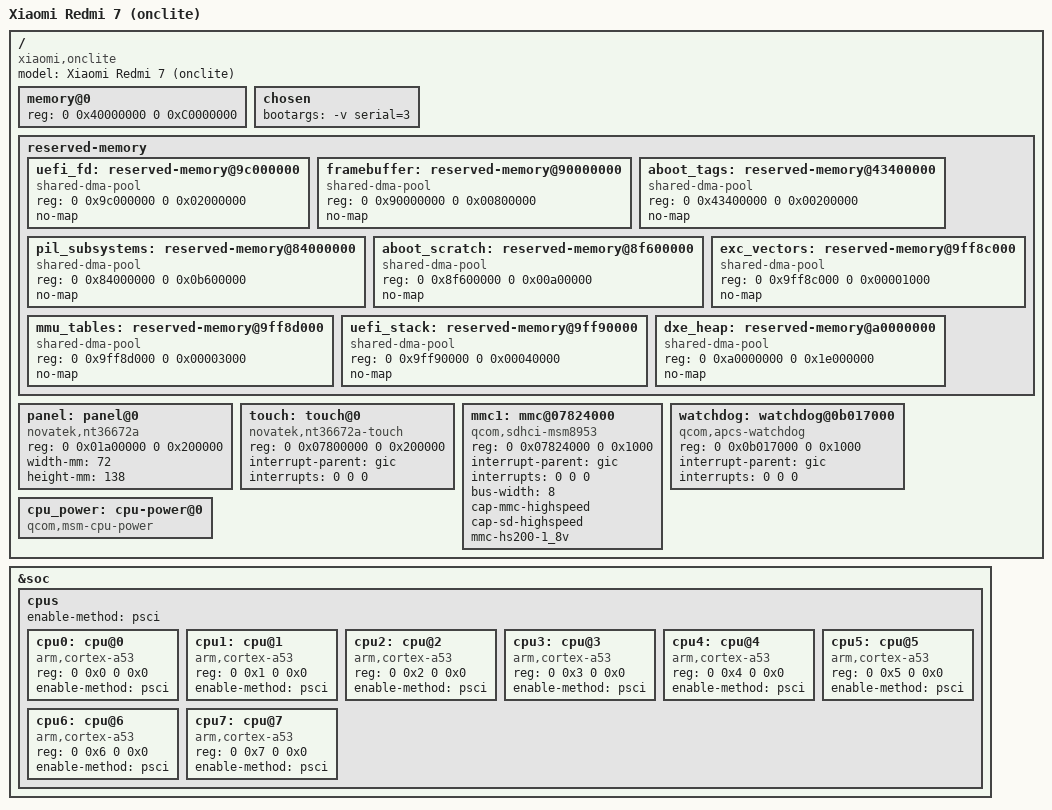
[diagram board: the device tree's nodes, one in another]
/dts-v1/;
/include/ "msm8953.dtsi"

/ {
    model = "Xiaomi Redmi 7 (onclite)";
    compatible = "xiaomi,onclite", "qcom,msm8953";

    // 3 GiB LPDDR3: Bank0 0x40000000-0x80000000 + Bank1 0x80000000-0x100000000
    memory@0 {
        device_type = "memory";
        reg = <0 0x40000000 0 0xC0000000>;
    };

    chosen {
        bootargs = "-v serial=3";
    };

    reserved-memory {
        #address-cells = <2>;
        #size-cells = <2>;
        ranges;

        // UEFI Firmware Device (32 MiB)
        uefi_fd: reserved-memory@9c000000 {
            compatible = "shared-dma-pool", "qcom,uefi-fd";
            reg = <0 0x9c000000 0 0x02000000>;
            no-map;
        };

        // FrameBuffer Continuous Splash (MDP5 scanout, 720x1520 32bpp)
        framebuffer: reserved-memory@90000000 {
            compatible = "shared-dma-pool", "qcom,framebuffer";
            reg = <0 0x90000000 0 0x00800000>;
            no-map;
        };

        // ABOOT tags & Flattened Device Tree
        aboot_tags: reserved-memory@43400000 {
            compatible = "shared-dma-pool", "qcom,aboot-tags";
            reg = <0 0x43400000 0 0x00200000>;
            no-map;
        };

        // PIL Subsystems (Modem, ADSP, WCNSS, Venus, SMEM)
        pil_subsystems: reserved-memory@84000000 {
            compatible = "shared-dma-pool", "qcom,pil-subsystems";
            reg = <0 0x84000000 0 0x0b600000>;
            no-map;
        };

        // ABOOT / lk2nd Execution & Scratch Region
        aboot_scratch: reserved-memory@8f600000 {
            compatible = "shared-dma-pool", "qcom,aboot-scratch";
            reg = <0 0x8f600000 0 0x00a00000>;
            no-map;
        };

        // CPU Exception Vectors
        exc_vectors: reserved-memory@9ff8c000 {
            compatible = "shared-dma-pool", "qcom,exc-vectors";
            reg = <0 0x9ff8c000 0 0x00001000>;
            no-map;
        };

        // MMU Translation Tables
        mmu_tables: reserved-memory@9ff8d000 {
            compatible = "shared-dma-pool", "qcom,mmu-tables";
            reg = <0 0x9ff8d000 0 0x00003000>;
            no-map;
        };

        // Primary UEFI Execution Stack
        uefi_stack: reserved-memory@9ff90000 {
            compatible = "shared-dma-pool", "qcom,uefi-stack";
            reg = <0 0x9ff90000 0 0x00040000>;
            no-map;
        };

        // DXE Heap (Executable Memory Pool for DXE Drivers)
        dxe_heap: reserved-memory@a0000000 {
            compatible = "shared-dma-pool", "qcom,dxe-heap";
            reg = <0 0xa0000000 0 0x1e000000>;
            no-map;
        };
    };

    // Display panel (Novatek NT36672A or Synaptics DSX, 720x1520)
    panel: panel@0 {
        compatible = "novatek,nt36672a", "synaptics,dsx";
        reg = <0 0x01a00000 0 0x200000>;
        width-mm = <72>;
        height-mm = <138>;
    };

    // Touch controller (Novatek NT36672A touch or Synaptics DSX)
    touch: touch@0 {
        compatible = "novatek,nt36672a-touch", "synaptics,dsx-touch";
        reg = <0 0x07800000 0 0x200000>;
        interrupt-parent = <&gic>;
        interrupts = <0 0 0>;
    };

    // eMMC storage (MSM SDC1)
    mmc1: mmc@07824000 {
        compatible = "qcom,sdhci-msm8953";
        reg = <0 0x07824000 0 0x1000>;
        interrupt-parent = <&gic>;
        interrupts = <0 0 0>;
        bus-width = <8>;
        cap-mmc-highspeed;
        cap-sd-highspeed;
        mmc-hs200-1_8v;
    };

    // APCS Watchdog
    watchdog: watchdog@0b017000 {
        compatible = "qcom,apcs-watchdog";
        reg = <0 0x0b017000 0 0x1000>;
        interrupt-parent = <&gic>;
        interrupts = <0 0 0>;
    };

    // CPU power domain
    cpu_power: cpu-power@0 {
        compatible = "qcom,msm-cpu-power";
    };
};

// CPUs (Kryo 250 / Cortex-A53, 8 cores)
&soc {
    cpus: cpus {
        #address-cells = <2>;
        #size-cells = <0>;
        enable-method = "psci";

        cpu0: cpu@0 {
            device_type = "cpu";
            compatible = "arm,cortex-a53";
            reg = <0 0x0 0 0x0>;
            enable-method = "psci";
            device_type = "cpu";
        };

        cpu1: cpu@1 {
            device_type = "cpu";
            compatible = "arm,cortex-a53";
            reg = <0 0x1 0 0x0>;
            enable-method = "psci";
        };

        cpu2: cpu@2 {
            device_type = "cpu";
            compatible = "arm,cortex-a53";
            reg = <0 0x2 0 0x0>;
            enable-method = "psci";
        };

        cpu3: cpu@3 {
            device_type = "cpu";
            compatible = "arm,cortex-a53";
            reg = <0 0x3 0 0x0>;
            enable-method = "psci";
        };

        cpu4: cpu@4 {
            device_type = "cpu";
            compatible = "arm,cortex-a53";
            reg = <0 0x4 0 0x0>;
            enable-method = "psci";
        };

        cpu5: cpu@5 {
            device_type = "cpu";
            compatible = "arm,cortex-a53";
            reg = <0 0x5 0 0x0>;
            enable-method = "psci";
        };

        cpu6: cpu@6 {
            device_type = "cpu";
            compatible = "arm,cortex-a53";
            reg = <0 0x6 0 0x0>;
            enable-method = "psci";
        };

        cpu7: cpu@7 {
            device_type = "cpu";
            compatible = "arm,cortex-a53";
            reg = <0 0x7 0 0x0>;
            enable-method = "psci";
        };
    };
};

// Set CPU status, reserved memory, peripheral wiring, and firmware inputs
// from this board's hardware documentation.
